# STM32N645 register map
File version: 1.0
CPU: CM55 r0p1, little endian, no MPU, FPU, vendor SysTick, 8 interrupt priority bits
Registers are 32-bit, read-write, reset 0x0 unless marked. A register's access mark holds for its fields unless they carry their own. Offsets are from the block's base; [hi:lo] are bit positions; {n}, {i} and the like mark numbered series.

## RNG — True random number generator
Base 0x44020000
Same registers: RNG_S 0x54020000
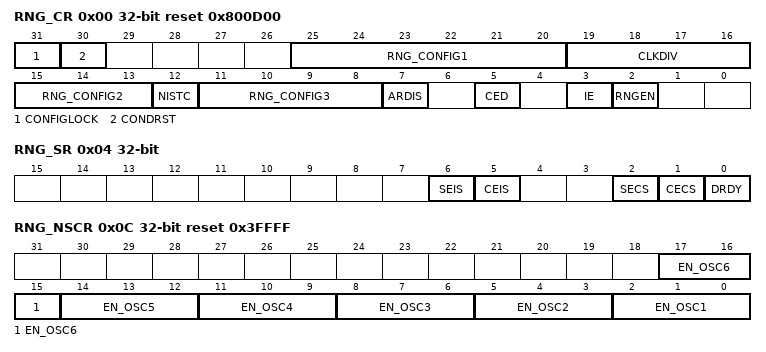
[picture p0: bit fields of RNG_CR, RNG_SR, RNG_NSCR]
0x00 RNG_CR reset 0x800D00 — RNG control register
  [31] CONFIGLOCK — RNG Config lock
    0=Writes to the RNG_NSCR, RNG_HTCR and RNG_CR configuration bits [29:4] are allowed; 1=Writes to the RNG_NSCR, RNG_HTCR and RNG_CR configuration bits [29:4] are ignored until the next RNG reset
  [30] CONDRST — Conditioning soft reset
  [25:20] RNG_CONFIG1 — RNG configuration 1
  [19:16] CLKDIV — Clock divider factor
    0=internal RNG clock after divider is similar to incoming RNG clock; 1=two RNG clock cycles per internal RNG clock; 2=2 less than sup>2 less than /sup> (= 4) RNG clock cycles per internal RNG clock; 15=2 less than sup>15 less than /sup> RNG clock cycles per internal clock (for example. an incoming 48 MHz RNG clock becomes a 1.5 kHz internal RNG clock)
  [15:13] RNG_CONFIG2 — RNG configuration 2
  [12] NISTC — NIST custom
    0=Hardware default values for NIST compliant RNG. In this configuration per 128-bit output; 1=Custom values for NIST compliant RNG. See Section 47.6: RNG entropy source validation for proposed configuration.
  [11:8] RNG_CONFIG3 — RNG configuration 3
  [7] ARDIS — Auto reset disable
    0=When a noise source error occurs RNG performs an automatic reset to clear the SECS bit; 1=When a noise source error occurs the application must reset RNG by writing CONDRST to 1 then to 0, in order to restart random number generation
  [5] CED — Clock error detection
    0=Clock error detection enabled; 1=Clock error detection is disabled
  [3] IE — Interrupt enable
    0=RNG interrupt is disabled; 1=RNG interrupt is enabled. An interrupt is pending as soon as DRDY = 1, SEIS = 1 or CEIS = 1 in the RNG_SR register.
  [2] RNGEN — True random number generator enable
    0=True random number generator is disabled. Analog noise sources are powered off and logic clocked by the RNG clock is gated.; 1=True random number generator is enabled
0x04 RNG_SR access per field — RNG status register
  [6] SEIS rw — Seed error interrupt status
    0=No faulty sequence detected; 1=At least one faulty sequence is detected. See SECS bit description for details.
  [5] CEIS rw — Clock error interrupt status
    0=The RNG clock is correct (f less than sub>RNGCLK less than /sub>> f less than sub>HCLK less than /sub>/32); 1=The RNG clock before the internal divider is detected too slow (f less than sub>RNGCLK less than /sub> less than f less than sub>HCLK less than /sub>/32)
  [2] SECS ro — Seed error current status
    0=No faulty sequence has currently been detected. If the SEIS bit is set, this means that a faulty sequence was detected and the situation has been recovered.; 1=At least one of the following faulty sequences has been detected:
  [1] CECS ro — Clock error current status
    0=The RNG clock is correct (f less than sub>RNGCLK less than /sub>> f less than sub>HCLK less than /sub>/32). If the CEIS bit is set, this means that a slow clock was detected and the situation has been recovered.; 1=The RNG clock is too slow (f less than sub>RNGCLK less than /sub> less than f less than sub>HCLK less than /sub>/32)
  [0] DRDY ro — Data ready
    0=The RNG_DR register is not yet valid, no random data is available; 1=The RNG_DR register contains valid random data
0x08 RNG_DR ro — RNG data register
  [31:0] RNDATA — Random data
0x0C RNG_NSCR reset 0x3FFFF — RNG noise source control register
  [3n-1:3n-3] EN_OSC{n} (n=1..6) — Each bit drives one oscillator enable signal input of instance number {n}, gated with the RNGEN bit in RNG_CR (set bit to enable the oscillator). Bit is ignored otherwise.
0x10 RNG_HTCR reset 0x72AC — RNG health test control register
  [31:0] HTCFG — health test configuration
